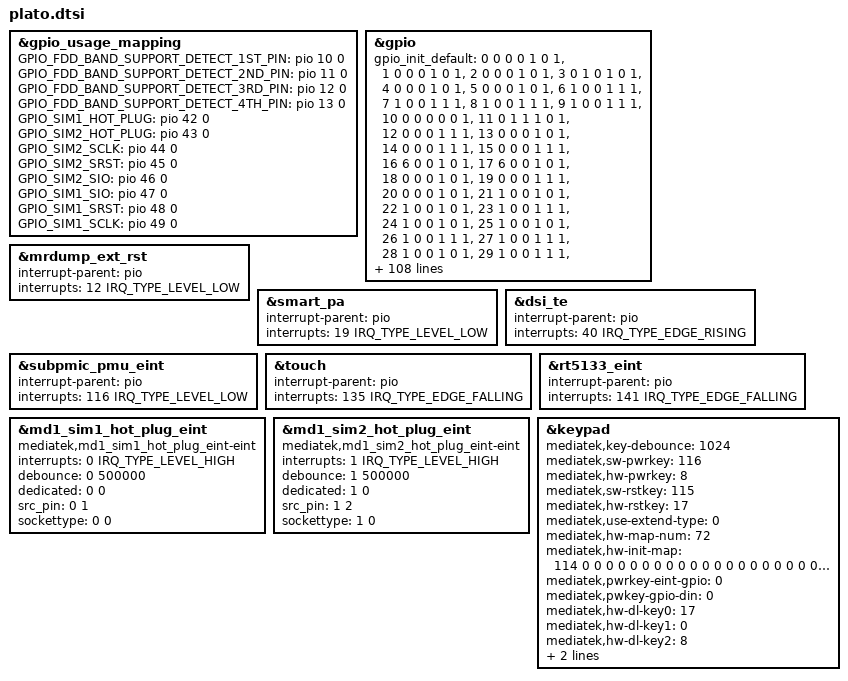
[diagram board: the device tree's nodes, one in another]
/*
 * Generated by MTK SP DrvGen Version: 3.5.160809 for MT6895.
 * Do Not Modify The File.
 * Copyright Mediatek Inc. (c) 2016.
*/

/*************************
 * ADC DTSI File
*************************/



/*************************
 * CLK_BUF DTSI File
*************************/



/*************************
 * I2C DTSI File
*************************/



/*************************
 * GPIO DTSI File
*************************/

&gpio_usage_mapping {
	GPIO_FDD_BAND_SUPPORT_DETECT_1ST_PIN = <&pio 10 0>;
    GPIO_FDD_BAND_SUPPORT_DETECT_2ND_PIN = <&pio 11 0>;
    GPIO_FDD_BAND_SUPPORT_DETECT_3RD_PIN = <&pio 12 0>;
    GPIO_FDD_BAND_SUPPORT_DETECT_4TH_PIN = <&pio 13 0>;
	GPIO_SIM1_HOT_PLUG = <&pio 42 0>;
	GPIO_SIM2_HOT_PLUG = <&pio 43 0>;
	GPIO_SIM2_SCLK = <&pio 44 0>;
	GPIO_SIM2_SRST = <&pio 45 0>;
	GPIO_SIM2_SIO = <&pio 46 0>;
	GPIO_SIM1_SIO = <&pio 47 0>;
	GPIO_SIM1_SRST = <&pio 48 0>;
	GPIO_SIM1_SCLK = <&pio 49 0>;
};

&gpio{
	gpio_init_default = <0 0 0 0 1 0 1>,
		<1 0 0 0 1 0 1>,
		<2 0 0 0 1 0 1>,
		<3 0 1 0 1 0 1>,
		<4 0 0 0 1 0 1>,
		<5 0 0 0 1 0 1>,
		<6 1 0 0 1 1 1>,
		<7 1 0 0 1 1 1>,
		<8 1 0 0 1 1 1>,
		<9 1 0 0 1 1 1>,
		<10 0 0 0 0 0 1>,
		<11 0 1 1 1 0 1>,
		<12 0 0 0 1 1 1>,
		<13 0 0 0 1 0 1>,
		<14 0 0 0 1 1 1>,
		<15 0 0 0 1 1 1>,
		<16 6 0 0 1 0 1>,
		<17 6 0 0 1 0 1>,
		<18 0 0 0 1 0 1>,
		<19 0 0 0 1 1 1>,
		<20 0 0 0 1 0 1>,
		<21 1 0 0 1 0 1>,
		<22 1 0 0 1 0 1>,
		<23 1 0 0 1 1 1>,
		<24 1 0 0 1 0 1>,
		<25 1 0 0 1 0 1>,
		<26 1 0 0 1 1 1>,
		<27 1 0 0 1 1 1>,
		<28 1 0 0 1 0 1>,
		<29 1 0 0 1 1 1>,
		<30 1 0 0 1 1 1>,
		<31 1 0 0 1 1 1>,
		<32 1 0 0 1 1 1>,
		<33 1 0 0 1 1 1>,
		<34 1 0 0 1 1 1>,
		<35 1 0 0 1 1 1>,
		<36 1 0 0 1 1 1>,
		<37 1 0 0 1 1 1>,
		<38 1 0 0 1 1 1>,
		<39 1 0 0 0 0 1>,
		<40 1 0 0 1 0 1>,
		<41 0 1 0 1 0 0>,
		<42 1 0 0 1 1 1>,
		<43 0 0 0 1 0 1>,
		<44 1 0 0 0 0 1>,
		<45 1 0 0 0 0 1>,
		<46 1 0 0 1 1 1>,
		<47 1 0 0 1 1 1>,
		<48 1 0 0 0 0 1>,
		<49 1 0 0 0 0 1>,
		<50 1 0 0 0 0 1>,
		<51 1 0 0 1 1 1>,
		<52 1 0 0 1 1 1>,
		<53 1 0 0 1 1 1>,
		<54 1 0 0 1 1 1>,
		<55 1 0 0 1 1 1>,
		<56 1 0 0 1 0 1>,
		<57 1 0 0 1 0 1>,
		<58 1 0 0 0 0 1>,
		<59 1 0 0 0 0 1>,
		<60 1 0 0 0 0 1>,
		<61 1 0 0 0 0 1>,
		<62 1 0 0 0 0 1>,
		<63 1 0 0 0 0 1>,
		<64 1 0 0 0 0 1>,
		<65 1 0 0 0 0 1>,
		<66 1 0 0 0 0 1>,
		<67 1 0 0 0 0 1>,
		<68 1 0 0 0 0 1>,
		<69 1 0 0 0 0 1>,
		<70 1 0 0 0 0 1>,
		<71 1 0 0 0 0 1>,
		<72 1 0 0 0 0 1>,
		<73 3 0 0 0 0 1>,
		<74 3 0 0 0 0 1>,
		<75 1 0 0 0 0 1>,
		<76 1 0 0 0 0 1>,
		<77 1 0 0 0 0 1>,
		<78 4 0 0 0 0 0>,
		<79 3 0 0 0 0 0>,
		<80 1 0 0 0 0 0>,
		<81 1 0 0 1 0 0>,
		<82 1 0 0 1 0 0>,
		<83 1 0 0 1 0 0>,
		<84 1 0 0 0 0 0>,
		<85 1 0 0 1 0 0>,
		<86 1 0 0 0 0 0>,
		<87 1 0 0 1 0 0>,
		<88 1 0 0 1 1 1>,
		<89 1 0 0 0 0 1>,
		<90 1 0 0 1 1 1>,
		<91 1 0 0 0 0 1>,
		<92 7 0 0 1 0 1>,
		<93 7 0 0 1 0 1>,
		<94 7 0 0 1 0 1>,
		<95 3 0 0 0 0 1>,
		<96 3 0 0 1 0 1>,
		<97 3 0 0 1 0 1>,
		<98 3 0 0 1 0 1>,
		<99 7 0 0 0 0 1>,
		<100 7 0 0 1 0 1>,
		<101 7 0 0 1 0 1>,
		<102 7 0 0 1 0 1>,
		<103 7 0 0 1 0 1>,
		<104 7 0 0 1 0 1>,
		<105 7 0 0 1 0 1>,
		<106 1 0 0 1 0 1>,
		<107 1 0 0 1 1 1>,
		<108 0 0 0 0 0 1>,
		<109 1 0 0 1 0 1>,
		<110 1 0 0 1 1 1>,
		<111 1 0 0 1 0 1>,
		<112 1 0 0 1 0 1>,
		<114 0 0 0 1 1 1>,
		<115 0 0 0 1 0 1>,
		<116 0 0 0 1 1 1>,
		<117 1 0 0 0 0 1>,
		<118 0 1 0 1 0 1>,
		<119 0 1 0 1 0 1>,
		<120 4 0 0 1 0 1>,
		<121 0 1 0 1 0 1>,
		<122 0 1 0 1 0 1>,
		<123 1 0 0 1 0 1>,
		<124 1 0 0 1 1 1>,
		<125 1 0 0 1 0 1>,
		<126 1 0 0 1 0 1>,
		<127 0 0 0 1 0 1>,
		<128 0 1 0 1 0 1>,
		<129 1 0 0 1 1 1>,
		<130 1 0 0 1 1 1>,
		<131 1 0 0 1 1 1>,
		<132 1 0 0 1 1 1>,
		<133 1 0 0 1 1 1>,
		<134 1 0 0 1 1 1>,
		<135 0 0 0 1 0 1>,
		<136 0 0 0 1 0 1>,
		<137 1 0 0 1 1 1>,
		<138 1 0 0 1 1 1>,
		<139 1 0 0 1 1 1>,
		<140 1 0 0 1 1 1>,
		<141 0 0 0 1 0 1>,
		<142 0 0 0 1 0 1>,
		<143 0 0 0 1 0 1>,
		<144 0 0 0 1 0 1>,
		<145 0 0 0 1 0 1>,
		<146 0 0 0 1 0 1>,
		<147 0 1 0 1 0 0>,
		<148 0 1 1 1 0 1>,
		<149 0 0 0 1 0 1>,
		<150 1 0 0 1 0 1>,
		<151 1 0 0 1 0 1>,
		<152 1 0 0 1 0 1>,
		<153 0 1 0 1 0 1>,
		<154 0 1 0 1 0 1>,
		<155 0 1 0 1 0 1>,
		<156 0 1 0 1 0 1>,
		<157 0 0 0 1 0 1>,
		<158 0 1 1 0 0 0>,
		<159 0 0 0 1 0 1>,
		<160 0 1 0 1 0 1>,
		<161 0 0 0 1 0 1>,
		<162 1 0 0 1 0 1>,
		<163 1 0 0 1 0 1>,
		<164 0 1 0 1 0 1>,
		<165 0 0 0 1 0 1>,
		<166 0 0 0 1 0 1>,
		<167 0 0 0 1 0 1>,
		<168 0 0 0 1 0 1>,
		<169 0 0 0 1 0 1>,
		<170 0 0 0 1 0 1>,
		<171 0 0 0 1 0 1>,
		<172 0 0 0 1 0 1>,
		<173 0 0 0 1 0 1>,
		<174 0 0 0 1 0 1>,
		<175 0 0 0 1 0 1>,
		<176 0 1 0 1 0 1>,
		<177 0 1 0 1 0 1>,
		<178 0 0 0 1 0 1>,
		<179 1 0 0 1 0 1>,
		<180 1 0 0 1 0 1>,
		<181 0 0 0 1 0 1>,
		<182 0 0 0 1 0 1>,
		<183 0 1 0 1 0 1>,
		<184 0 0 0 1 0 1>,
		<185 0 0 0 1 0 1>,
		<186 1 0 0 1 0 0>,
		<187 1 0 0 1 0 0>,
		<188 0 1 1 1 0 1>,
		<189 0 1 1 1 0 1>,
		<190 0 1 0 1 0 1>,
		<191 0 0 0 0 0 0>,
		<192 1 0 0 1 1 1>,
		<193 1 0 0 1 1 1>,
		<194 1 0 0 0 0 1>,
		<195 1 0 0 0 0 1>,
		<196 1 0 0 0 0 1>,
		<197 1 0 0 0 0 1>,
		<198 1 0 0 0 0 1>,
		<199 1 0 0 1 0 1>,
		<200 1 0 0 1 1 1>,
		<201 1 0 0 1 1 1>,
		<202 1 0 0 0 0 1>,
		<203 1 0 0 0 0 1>,
		<204 1 0 0 0 0 1>,
		<205 1 0 0 0 0 1>,
		<206 1 0 0 0 0 1>,
		<207 1 0 0 0 0 1>,
		<208 1 0 0 0 0 1>,
		<209 1 0 0 1 0 1>,
		<210 1 0 0 1 0 1>,
		<211 1 0 0 1 0 1>,
		<212 0 1 0 1 0 1>,
		<213 0 1 0 1 0 1>,
		<214 0 1 0 1 0 1>,
		<215 0 1 0 1 0 1>,
		<216 0 1 0 1 0 1>,
		<217 1 0 0 1 0 1>,
		<218 0 1 0 1 0 1>,
		<219 1 0 0 1 1 1>,
		<220 1 0 0 1 0 1>,
		<221 1 0 0 0 0 1>,
		<222 1 0 0 0 0 1>,
		<223 1 0 0 0 0 1>,
		<224 1 0 0 0 0 1>,
		<225 1 0 0 1 1 1>,
		<226 1 0 0 1 1 1>,
		<227 0 0 0 1 0 0>,
		<228 0 0 0 1 0 0>,
		<229 0 0 0 1 0 0>,
		<230 0 0 0 1 0 0>,
		<231 0 0 0 1 0 0>,
		<232 0 0 0 1 0 0>,
		<233 0 0 0 1 0 0>,
		<234 0 0 0 1 0 0>,
		<235 0 0 0 1 0 0>,
		<236 0 0 0 1 0 0>,
		<237 0 0 0 1 0 0>,
		<238 0 0 0 1 0 0>,
		<239 0 0 0 1 0 0>,
		<240 0 0 0 1 0 0>,
		<241 0 0 0 1 0 0>,
		<242 0 0 0 1 0 0>,
		<243 0 0 0 1 0 0>,
		<244 0 0 0 1 0 0>,
		<245 0 0 0 1 0 0>,
		<246 0 0 0 1 0 0>;
};


/*************************
 * EINT DTSI File
*************************/

#include <dt-bindings/interrupt-controller/irq.h>
#include <dt-bindings/interrupt-controller/arm-gic.h>

&mrdump_ext_rst {
	interrupt-parent = <&pio>;
	interrupts = <12 IRQ_TYPE_LEVEL_LOW>;
	status = "okay";
};

&smart_pa {
	interrupt-parent = <&pio>;
	interrupts = <19 IRQ_TYPE_LEVEL_LOW>;
	status = "okay";
};

&dsi_te {
	interrupt-parent = <&pio>;
	interrupts = <40 IRQ_TYPE_EDGE_RISING>;
	status = "okay";
};

&subpmic_pmu_eint {
	interrupt-parent = <&pio>;
	interrupts = <116 IRQ_TYPE_LEVEL_LOW>;
	status = "okay";
};

&touch {
	interrupt-parent = <&pio>;
	interrupts = <135 IRQ_TYPE_EDGE_FALLING>;
	status = "okay";
};

&rt5133_eint {
	interrupt-parent = <&pio>;
	interrupts = <141 IRQ_TYPE_EDGE_FALLING>;
	status = "okay";
};



/*************************
 * MD1_EINT DTSI File
*************************/

&md1_sim1_hot_plug_eint {
	compatible = "mediatek,md1_sim1_hot_plug_eint-eint";
	interrupts = <0 IRQ_TYPE_LEVEL_HIGH>;
	debounce = <0 500000>;
	dedicated = <0 0>;
	src_pin = <0 1>;
	sockettype = <0 0>;
	status = "okay";
};

&md1_sim2_hot_plug_eint {
	compatible = "mediatek,md1_sim2_hot_plug_eint-eint";
	interrupts = <1 IRQ_TYPE_LEVEL_HIGH>;
	debounce = <1 500000>;
	dedicated = <1 0>;
	src_pin = <1 2>;
	sockettype = <1 0>;
	status = "okay";
};

/*************************
 * PMIC DTSI File
*************************/



/*************************
 * POWER DTSI File
*************************/



/*************************
 * KPD DTSI File
*************************/

&keypad {
	mediatek,key-debounce = <1024>;
	mediatek,sw-pwrkey = <116>;
	mediatek,hw-pwrkey = <8>;
	mediatek,sw-rstkey  = <115>;
	mediatek,hw-rstkey = <17>;
	mediatek,use-extend-type = <0>;
	/*HW Keycode [0~71] -> Linux Keycode*/
	mediatek,hw-map-num = <72>;
	mediatek,hw-init-map = <114 0 0 0 0 0 0 0 0 0 0 0 0 0 0 0 0 0 0 0 0 0 0 0 0 0 0 0 0 0 0 0 0 0 0 0 0 0 0 0 0 0 0 0 0 0 0 0 0 0 0 0 0 0 0 0 0 0 0 0 0 0 0 0 0 0 0 0 0 0 0 0 >;
	mediatek,pwrkey-eint-gpio = <0>;
	mediatek,pwkey-gpio-din  = <0>;
	mediatek,hw-dl-key0 = <17>;
	mediatek,hw-dl-key1 = <0>;
	mediatek,hw-dl-key2 = <8>;
	mediatek,hw-recovery-key = <17>;
	mediatek,hw-factory-key = <0>;
	status = "okay";
};
